# iostm32f205zx register map
Registers are 32-bit, access not given, no defined reset value unless marked. A register's access mark holds for its fields unless they carry their own. Addresses are absolute; registers are grouped by the start of their names; [hi:lo] are bit positions; {n}, {i} and the like mark numbered series.

## TIM2
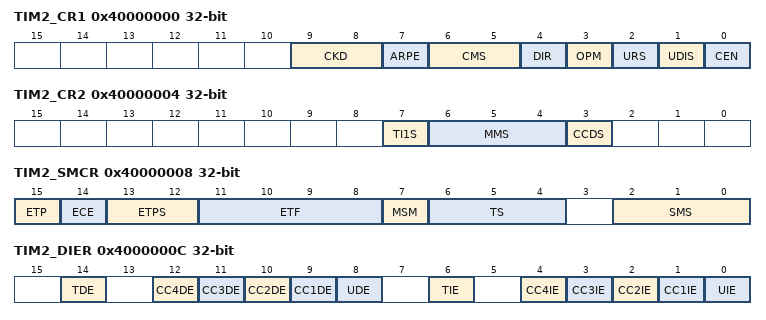
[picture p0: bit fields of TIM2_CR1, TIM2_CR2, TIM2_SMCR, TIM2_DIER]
0x40000000 TIM2_CR1
  [9:8] CKD, [7] ARPE, [6:5] CMS, [4] DIR, [3] OPM, [2] URS, [1] UDIS, [0] CEN
0x40000004 TIM2_CR2
  [7] TI1S, [6:4] MMS, [3] CCDS
0x40000008 TIM2_SMCR
  [15] ETP, [14] ECE, [13:12] ETPS, [11:8] ETF, [7] MSM, [6:4] TS, [2:0] SMS
0x4000000C TIM2_DIER
  [14] TDE, [n+8] CC{n}DE (n=1..4), [8] UDE, [6] TIE, [n] CC{n}IE (n=1..4), [0] UIE
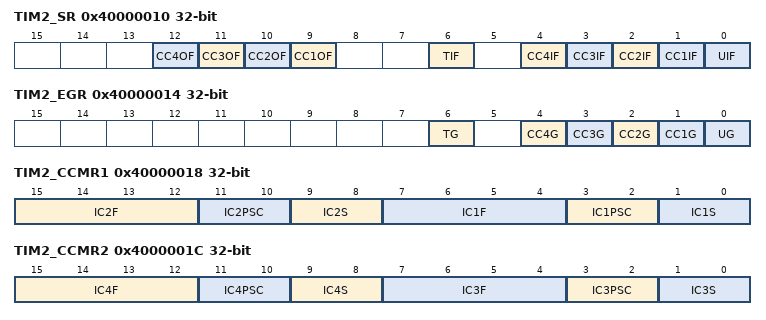
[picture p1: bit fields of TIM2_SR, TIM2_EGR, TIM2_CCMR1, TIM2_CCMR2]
0x40000010 TIM2_SR
  [n+8] CC{n}OF (n=1..4), [6] TIF, [n] CC{n}IF (n=1..4), [0] UIF
0x40000014 TIM2_EGR
  [6] TG, [n] CC{n}G (n=1..4), [0] UG
0x40000018 TIM2_CCMR1
  [15:12] IC2F, [11:10] IC2PSC, [9:8] IC2S, [7:4] IC1F, [3:2] IC1PSC, [1:0] IC1S
0x40000018 TIM2_OCMR1
0x4000001C TIM2_CCMR2
  [15:12] IC4F, [11:10] IC4PSC, [9:8] IC4S, [7:4] IC3F, [3:2] IC3PSC, [1:0] IC3S
0x4000001C TIM2_OCMR2
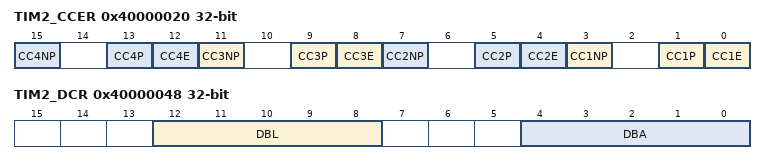
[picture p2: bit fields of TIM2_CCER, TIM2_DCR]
0x40000020 TIM2_CCER
  [4n-1] CC{n}NP (n=1..4), [4n-3] CC{n}P (n=1..4), [4n-4] CC{n}E (n=1..4)
0x40000024 TIM2_CNT
0x40000028 TIM2_PSC
  [15:0] PSC
0x4000002C TIM2_ARR
{0x40000030+4i} TIM2_CCR{i} (i=1..4)
0x40000048 TIM2_DCR
  [12:8] DBL, [4:0] DBA
0x4000004C TIM2_DMAR
  [15:0] DMAB
0x40000050 TIM2_OR
  [11:10] ITR1_RMP

## TIM3
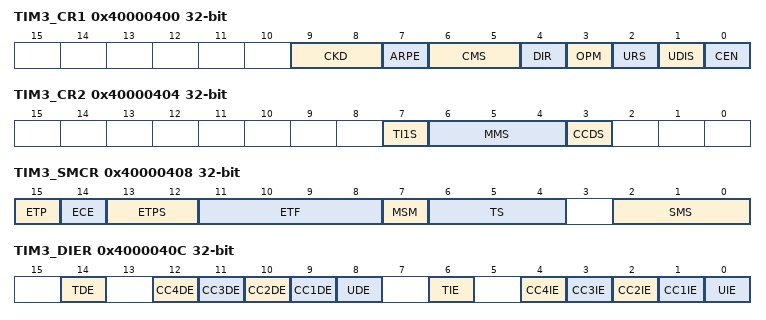
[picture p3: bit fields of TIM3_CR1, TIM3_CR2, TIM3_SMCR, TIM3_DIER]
0x40000400 TIM3_CR1
  [9:8] CKD, [7] ARPE, [6:5] CMS, [4] DIR, [3] OPM, [2] URS, [1] UDIS, [0] CEN
0x40000404 TIM3_CR2
  [7] TI1S, [6:4] MMS, [3] CCDS
0x40000408 TIM3_SMCR
  [15] ETP, [14] ECE, [13:12] ETPS, [11:8] ETF, [7] MSM, [6:4] TS, [2:0] SMS
0x4000040C TIM3_DIER
  [14] TDE, [n+8] CC{n}DE (n=1..4), [8] UDE, [6] TIE, [n] CC{n}IE (n=1..4), [0] UIE
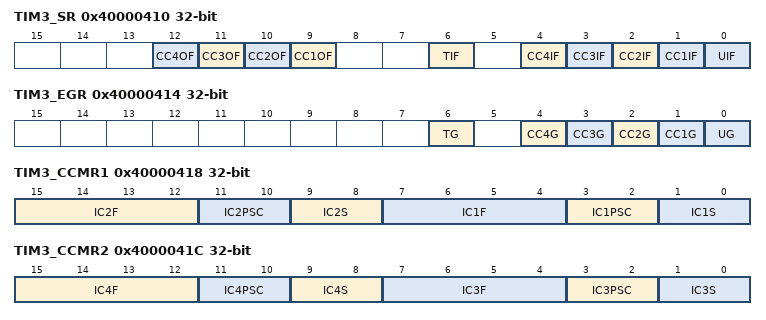
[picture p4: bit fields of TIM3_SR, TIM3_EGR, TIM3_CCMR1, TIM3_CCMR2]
0x40000410 TIM3_SR
  [n+8] CC{n}OF (n=1..4), [6] TIF, [n] CC{n}IF (n=1..4), [0] UIF
0x40000414 TIM3_EGR
  [6] TG, [n] CC{n}G (n=1..4), [0] UG
0x40000418 TIM3_CCMR1
  [15:12] IC2F, [11:10] IC2PSC, [9:8] IC2S, [7:4] IC1F, [3:2] IC1PSC, [1:0] IC1S
0x40000418 TIM3_OCMR1
0x4000041C TIM3_CCMR2
  [15:12] IC4F, [11:10] IC4PSC, [9:8] IC4S, [7:4] IC3F, [3:2] IC3PSC, [1:0] IC3S
0x4000041C TIM3_OCMR2
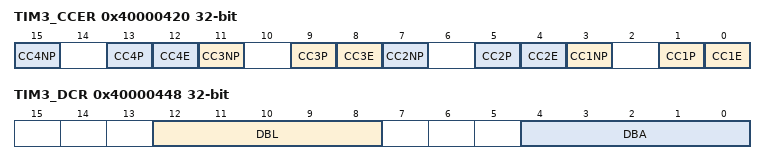
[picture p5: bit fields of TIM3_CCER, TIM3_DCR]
0x40000420 TIM3_CCER
  [4n-1] CC{n}NP (n=1..4), [4n-3] CC{n}P (n=1..4), [4n-4] CC{n}E (n=1..4)
0x40000424 TIM3_CNT
0x40000428 TIM3_PSC
  [15:0] PSC
0x4000042C TIM3_ARR
0x40000434 TIM3_CCR1
0x40000438 TIM3_CCR2
0x40000448 TIM3_DCR
  [12:8] DBL, [4:0] DBA
0x4000044C TIM3_DMAR
  [15:0] DMAB

## TIM4
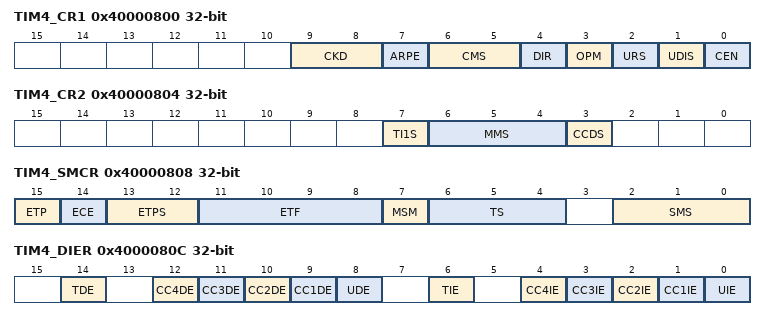
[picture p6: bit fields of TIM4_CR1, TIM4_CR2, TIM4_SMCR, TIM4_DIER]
0x40000800 TIM4_CR1
  [9:8] CKD, [7] ARPE, [6:5] CMS, [4] DIR, [3] OPM, [2] URS, [1] UDIS, [0] CEN
0x40000804 TIM4_CR2
  [7] TI1S, [6:4] MMS, [3] CCDS
0x40000808 TIM4_SMCR
  [15] ETP, [14] ECE, [13:12] ETPS, [11:8] ETF, [7] MSM, [6:4] TS, [2:0] SMS
0x4000080C TIM4_DIER
  [14] TDE, [n+8] CC{n}DE (n=1..4), [8] UDE, [6] TIE, [n] CC{n}IE (n=1..4), [0] UIE
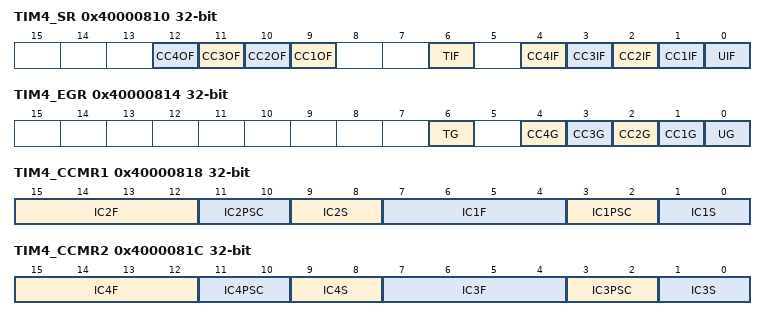
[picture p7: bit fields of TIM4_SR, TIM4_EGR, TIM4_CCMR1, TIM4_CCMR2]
0x40000810 TIM4_SR
  [n+8] CC{n}OF (n=1..4), [6] TIF, [n] CC{n}IF (n=1..4), [0] UIF
0x40000814 TIM4_EGR
  [6] TG, [n] CC{n}G (n=1..4), [0] UG
0x40000818 TIM4_CCMR1
  [15:12] IC2F, [11:10] IC2PSC, [9:8] IC2S, [7:4] IC1F, [3:2] IC1PSC, [1:0] IC1S
0x40000818 TIM4_OCMR1
0x4000081C TIM4_CCMR2
  [15:12] IC4F, [11:10] IC4PSC, [9:8] IC4S, [7:4] IC3F, [3:2] IC3PSC, [1:0] IC3S
0x4000081C TIM4_OCMR2
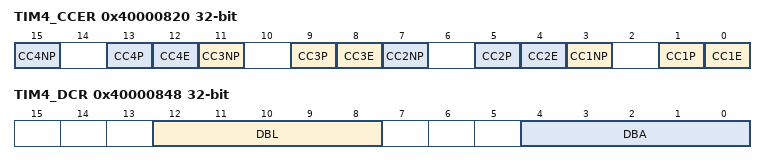
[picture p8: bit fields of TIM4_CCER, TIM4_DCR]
0x40000820 TIM4_CCER
  [4n-1] CC{n}NP (n=1..4), [4n-3] CC{n}P (n=1..4), [4n-4] CC{n}E (n=1..4)
0x40000824 TIM4_CNT
0x40000828 TIM4_PSC
  [15:0] PSC
0x4000082C TIM4_ARR
0x40000834 TIM4_CCR1
0x40000838 TIM4_CCR2
0x40000848 TIM4_DCR
  [12:8] DBL, [4:0] DBA
0x4000084C TIM4_DMAR
  [15:0] DMAB

## TIM5
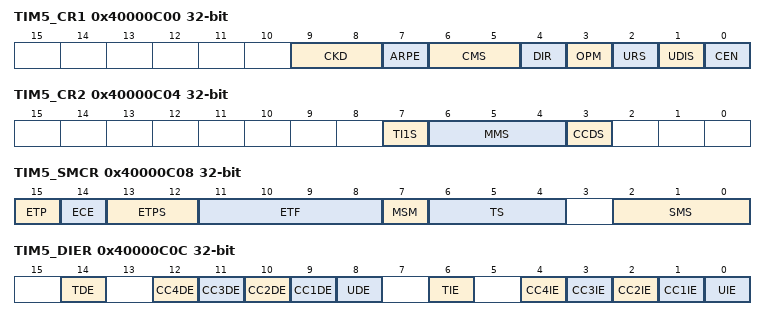
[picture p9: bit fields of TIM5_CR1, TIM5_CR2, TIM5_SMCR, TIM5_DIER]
0x40000C00 TIM5_CR1
  [9:8] CKD, [7] ARPE, [6:5] CMS, [4] DIR, [3] OPM, [2] URS, [1] UDIS, [0] CEN
0x40000C04 TIM5_CR2
  [7] TI1S, [6:4] MMS, [3] CCDS
0x40000C08 TIM5_SMCR
  [15] ETP, [14] ECE, [13:12] ETPS, [11:8] ETF, [7] MSM, [6:4] TS, [2:0] SMS
0x40000C0C TIM5_DIER
  [14] TDE, [n+8] CC{n}DE (n=1..4), [8] UDE, [6] TIE, [n] CC{n}IE (n=1..4), [0] UIE
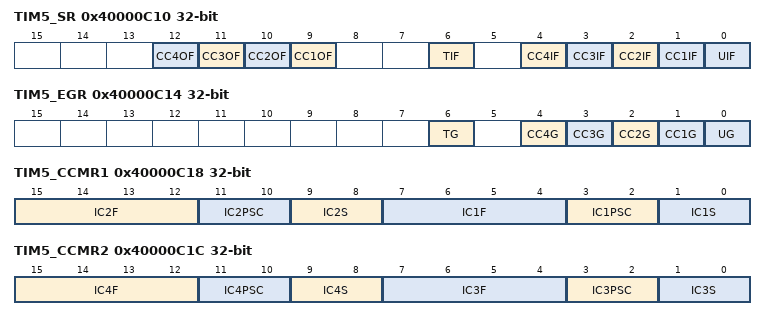
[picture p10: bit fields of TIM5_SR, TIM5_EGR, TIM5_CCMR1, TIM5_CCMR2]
0x40000C10 TIM5_SR
  [n+8] CC{n}OF (n=1..4), [6] TIF, [n] CC{n}IF (n=1..4), [0] UIF
0x40000C14 TIM5_EGR
  [6] TG, [n] CC{n}G (n=1..4), [0] UG
0x40000C18 TIM5_CCMR1
  [15:12] IC2F, [11:10] IC2PSC, [9:8] IC2S, [7:4] IC1F, [3:2] IC1PSC, [1:0] IC1S
0x40000C18 TIM5_OCMR1
0x40000C1C TIM5_CCMR2
  [15:12] IC4F, [11:10] IC4PSC, [9:8] IC4S, [7:4] IC3F, [3:2] IC3PSC, [1:0] IC3S
0x40000C1C TIM5_OCMR2
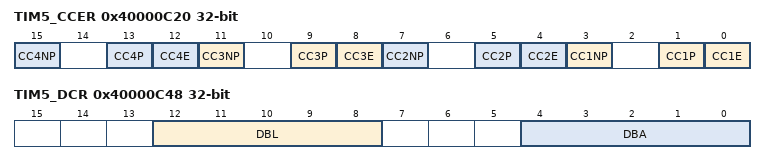
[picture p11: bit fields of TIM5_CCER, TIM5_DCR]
0x40000C20 TIM5_CCER
  [4n-1] CC{n}NP (n=1..4), [4n-3] CC{n}P (n=1..4), [4n-4] CC{n}E (n=1..4)
0x40000C24 TIM5_CNT
0x40000C28 TIM5_PSC
  [15:0] PSC
0x40000C2C TIM5_ARR
{0x40000C30+4i} TIM5_CCR{i} (i=1..4)
0x40000C48 TIM5_DCR
  [12:8] DBL, [4:0] DBA
0x40000C4C TIM5_DMAR
  [15:0] DMAB
0x40000C50 TIM5_OR
  [7:6] TI4_RMP
